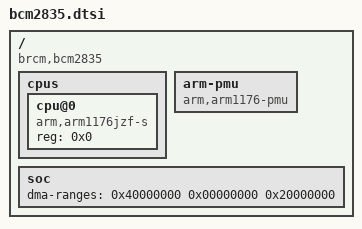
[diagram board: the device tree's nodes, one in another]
/* SPDX-License-Identifier: GPL-2.0-or-later */
#include "bcm283x.dtsi"
#include <dt-bindings/irq.h>

/ {
    compatible = "brcm,bcm2835";

    cpus {
        #address-cells = <1>;
        #size-cells = <0>;

        cpu@0 {
            device_type = "cpu";
            compatible = "arm,arm1176jzf-s";
            reg = <0x0>;
        };
    };

    arm-pmu {
        compatible = "arm,arm1176-pmu";
    };

    soc {
        ranges = <0x7e000000 0x20000000 0x02000000>;
        dma-ranges = <0x40000000 0x00000000 0x20000000>;
    };
};
